# MKE18F16 register map
Vendor: Freescale Semiconductor, Inc.; Series: Kinetis_E; File version: 1.6
CPU: CM4 r0p1, little endian, no MPU, FPU, VTOR, 4 interrupt priority bits
Registers are 32-bit, read-write, reset 0x0 unless marked. A register's access mark holds for its fields unless they carry their own. Offsets are from the block's base; [hi:lo] are bit positions; {n}, {i} and the like mark numbered series; 'fields as' and 'values as' point back to an identical list.

## PCC
Base 0x40065000
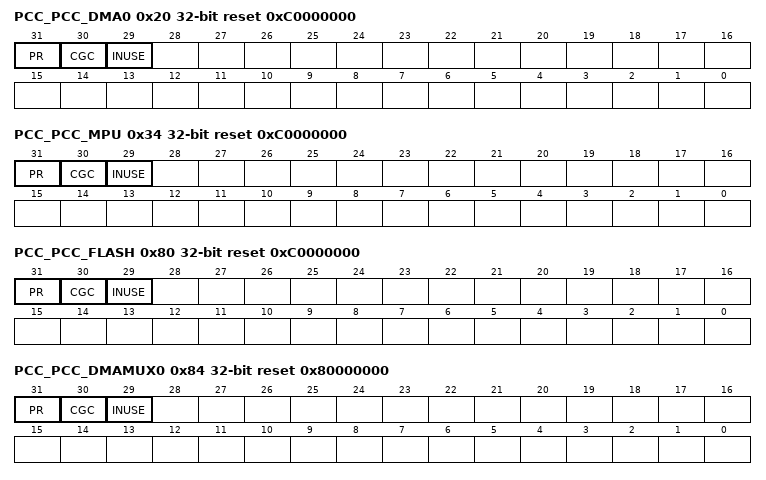
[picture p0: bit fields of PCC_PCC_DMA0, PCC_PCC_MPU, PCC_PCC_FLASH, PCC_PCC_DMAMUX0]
0x20 PCC_PCC_DMA0 reset 0xC0000000 — PCC Register
  [31] PR ro — Enable
    0=Peripheral is not present; 1=Peripheral is present
  [30] CGC — Clock Control
    0=Clock disabled; 1=Clock enabled
  [29] INUSE ro — Clock Gate Control
    0=Peripheral is not being used; 1=Peripheral is being used. Software cannot modify the existing clocking configuration.
0x34 PCC_PCC_MPU reset 0xC0000000 — PCC Register
  fields as PCC_PCC_DMA0
0x80 PCC_PCC_FLASH reset 0xC0000000 — PCC Register
  fields as PCC_PCC_DMA0
0x84 PCC_PCC_DMAMUX0 reset 0x80000000 — PCC Register
  fields as PCC_PCC_DMA0
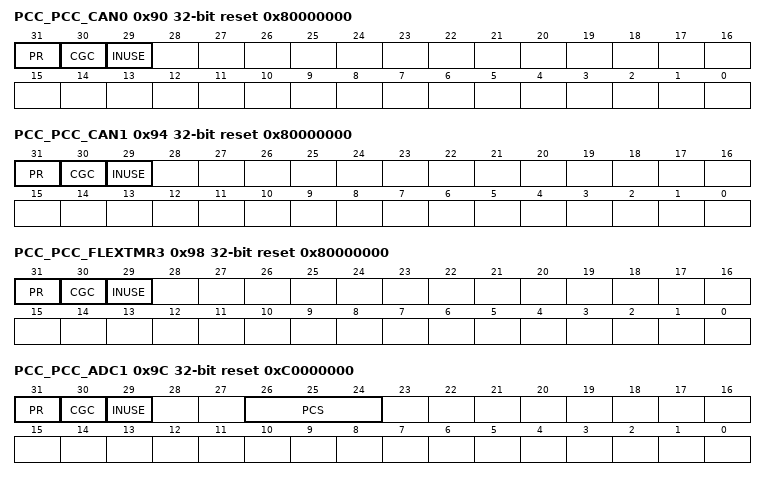
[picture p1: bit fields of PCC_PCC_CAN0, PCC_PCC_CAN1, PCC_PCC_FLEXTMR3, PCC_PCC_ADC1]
0x90 PCC_PCC_CAN0 reset 0x80000000 — PCC Register
  fields as PCC_PCC_DMA0
0x94 PCC_PCC_CAN1 reset 0x80000000 — PCC Register
  fields as PCC_PCC_DMA0
0x98 PCC_PCC_FLEXTMR3 reset 0x80000000 — PCC Register
  fields as PCC_PCC_DMA0
0x9C PCC_PCC_ADC1 reset 0xC0000000 — PCC Register
  [31] PR ro — Enable
    0=Peripheral is not present; 1=Peripheral is present
  [30] CGC — Clock Control
    0=Clock disabled; 1=Clock enabled
  [29] INUSE ro — Clock Gate Control
    values as PCC_PCC_DMA0.INUSE
  [26:24] PCS — Peripheral Clock Source Select
    0=Clock is off (or test clock is enabled); 1=OSCCLK - System Oscillator Bus Clock(scg_sosc_slow_clk); 2=SCGIRCLK - Slow IRC Clock(scg_sirc_slow_clk), (maximum is 8MHz); 3=SCGFIRCLK - Fast IRC Clock(scg_firc_slow_clk), (maximum is 48MHz); 6=SCGPCLK System PLL clock(scg_spll_slow_clk)
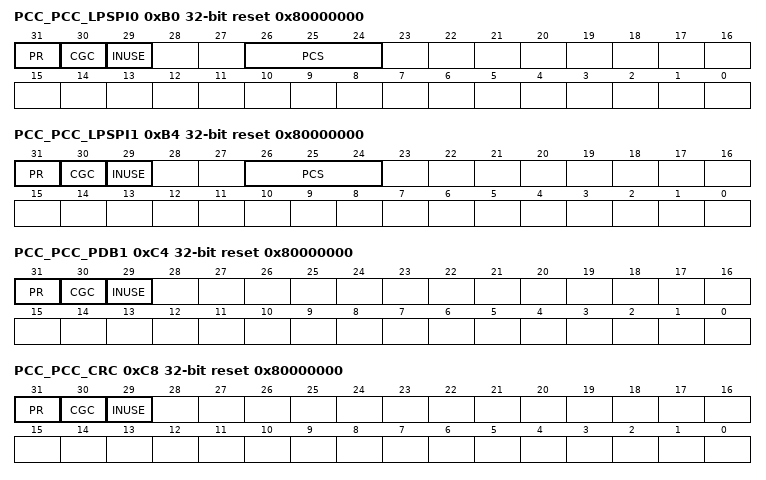
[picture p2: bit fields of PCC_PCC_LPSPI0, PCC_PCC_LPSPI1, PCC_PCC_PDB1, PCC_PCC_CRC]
0xB0 PCC_PCC_LPSPI0 reset 0x80000000 — PCC Register
  fields as PCC_PCC_ADC1
0xB4 PCC_PCC_LPSPI1 reset 0x80000000 — PCC Register
  fields as PCC_PCC_ADC1
0xC4 PCC_PCC_PDB1 reset 0x80000000 — PCC Register
  fields as PCC_PCC_DMA0
0xC8 PCC_PCC_CRC reset 0x80000000 — PCC Register
  fields as PCC_PCC_DMA0
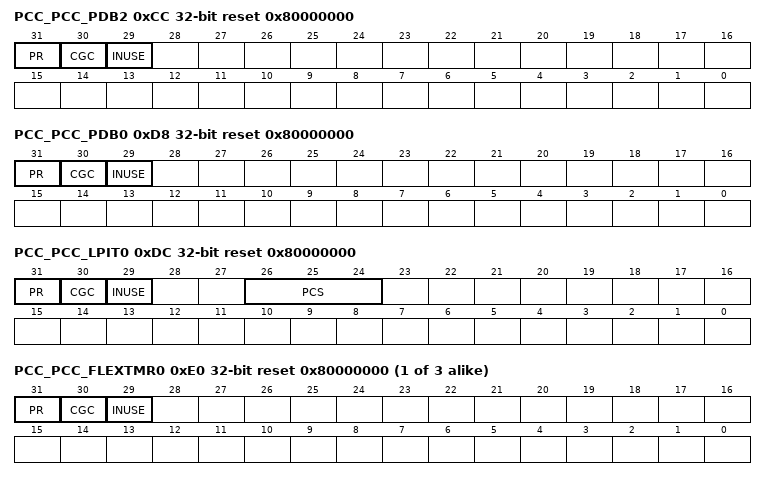
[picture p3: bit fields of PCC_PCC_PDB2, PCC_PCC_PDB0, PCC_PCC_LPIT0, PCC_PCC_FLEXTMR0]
0xCC PCC_PCC_PDB2 reset 0x80000000 — PCC Register
  fields as PCC_PCC_DMA0
0xD8 PCC_PCC_PDB0 reset 0x80000000 — PCC Register
  fields as PCC_PCC_DMA0
0xDC PCC_PCC_LPIT0 reset 0x80000000 — PCC Register
  fields as PCC_PCC_ADC1
{0xE0+4i} PCC_PCC_FLEXTMR{i} reset 0x80000000 (i=0..2) — PCC Register
  fields as PCC_PCC_DMA0
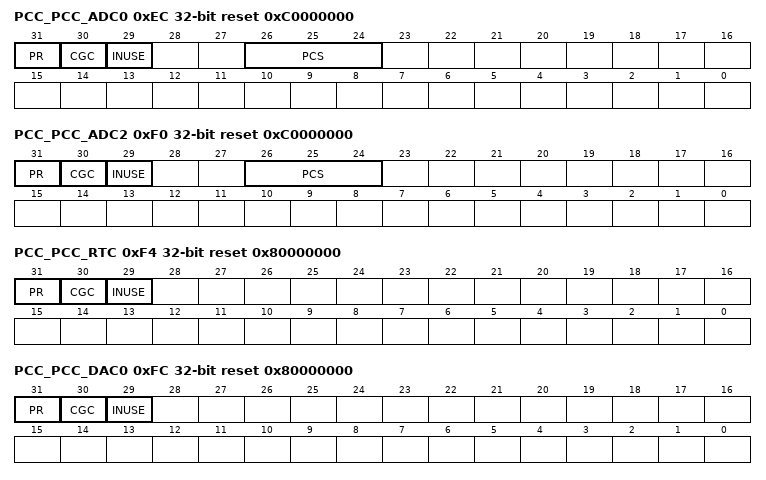
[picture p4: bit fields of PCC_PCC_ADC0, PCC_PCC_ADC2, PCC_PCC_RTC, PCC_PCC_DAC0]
0xEC PCC_PCC_ADC0 reset 0xC0000000 — PCC Register
  fields as PCC_PCC_ADC1
0xF0 PCC_PCC_ADC2 reset 0xC0000000 — PCC Register
  fields as PCC_PCC_ADC1
0xF4 PCC_PCC_RTC reset 0x80000000 — PCC Register
  fields as PCC_PCC_DMA0
0xFC PCC_PCC_DAC0 reset 0x80000000 — PCC Register
  fields as PCC_PCC_DMA0
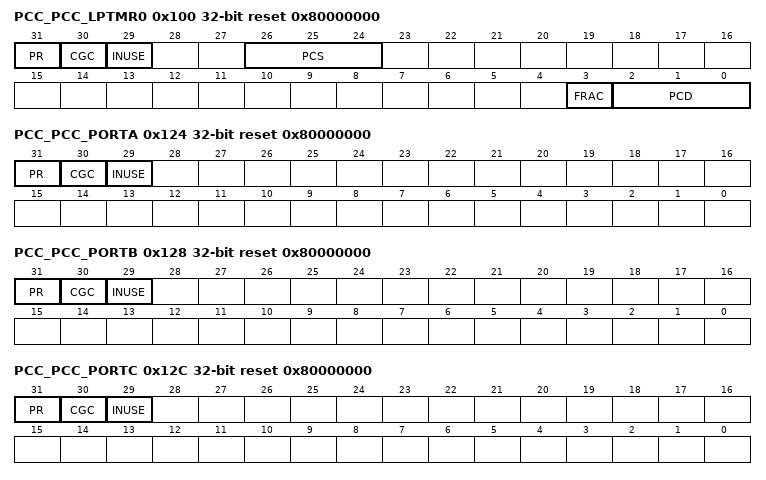
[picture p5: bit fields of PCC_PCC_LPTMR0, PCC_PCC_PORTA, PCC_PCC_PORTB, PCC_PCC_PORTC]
0x100 PCC_PCC_LPTMR0 reset 0x80000000 — PCC Register
  [31] PR ro — Enable
    0=Peripheral is not present; 1=Peripheral is present
  [30] CGC — Clock Control
    0=Clock disabled; 1=Clock enabled
  [29] INUSE ro — Clock Gate Control
    values as PCC_PCC_DMA0.INUSE
  [26:24] PCS — Peripheral Clock Source Select
    values as PCC_PCC_ADC1.PCS
  [3] FRAC — Peripheral Clock Divider Fraction
    0=Fractional value is 0; 1=Fractional value is 1
  [2:0] PCD — Peripheral Clock Divider Select
    0=Divide by 1 (pass-through, no clock divide); {v}=Divide by {v+1} (v=1..7)
0x124 PCC_PCC_PORTA reset 0x80000000 — PCC Register
  fields as PCC_PCC_DMA0
0x128 PCC_PCC_PORTB reset 0x80000000 — PCC Register
  fields as PCC_PCC_DMA0
0x12C PCC_PCC_PORTC reset 0x80000000 — PCC Register
  fields as PCC_PCC_DMA0
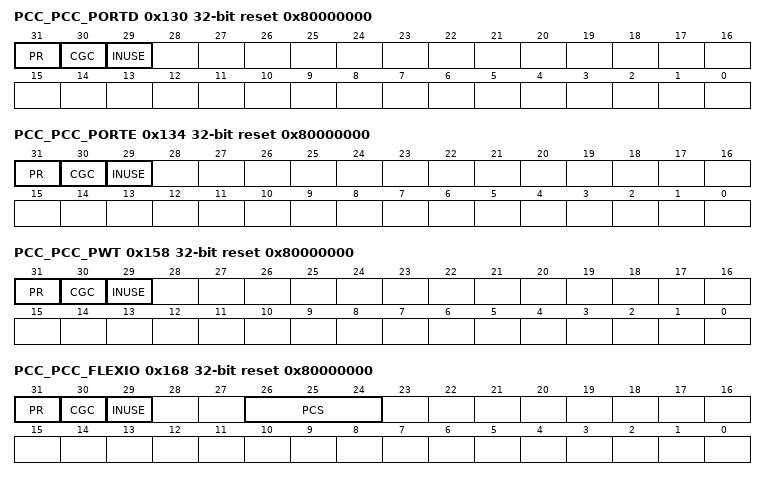
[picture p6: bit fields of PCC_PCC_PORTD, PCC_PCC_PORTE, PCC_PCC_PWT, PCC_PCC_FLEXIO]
0x130 PCC_PCC_PORTD reset 0x80000000 — PCC Register
  fields as PCC_PCC_DMA0
0x134 PCC_PCC_PORTE reset 0x80000000 — PCC Register
  fields as PCC_PCC_DMA0
0x158 PCC_PCC_PWT reset 0x80000000 — PCC Register
  fields as PCC_PCC_DMA0
0x168 PCC_PCC_FLEXIO reset 0x80000000 — PCC Register
  fields as PCC_PCC_ADC1
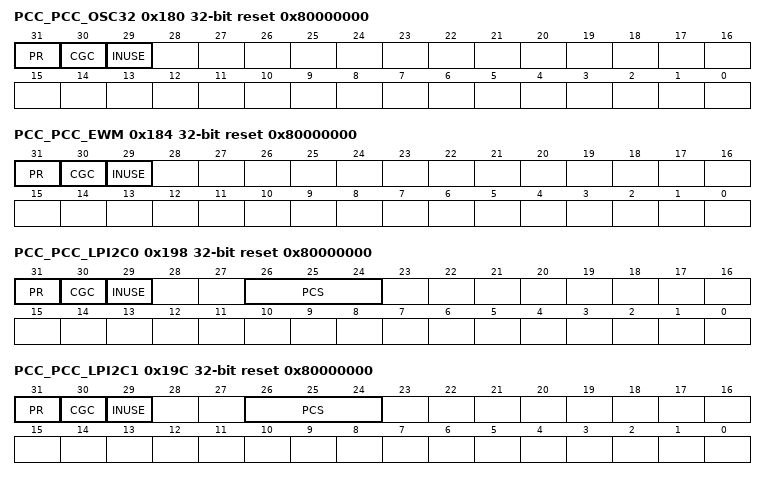
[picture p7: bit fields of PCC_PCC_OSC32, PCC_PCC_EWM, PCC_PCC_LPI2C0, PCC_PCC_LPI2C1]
0x180 PCC_PCC_OSC32 reset 0x80000000 — PCC Register
  fields as PCC_PCC_DMA0
0x184 PCC_PCC_EWM reset 0x80000000 — PCC Register
  fields as PCC_PCC_DMA0
0x198 PCC_PCC_LPI2C0 reset 0x80000000 — PCC Register
  fields as PCC_PCC_ADC1
0x19C PCC_PCC_LPI2C1 reset 0x80000000 — PCC Register
  fields as PCC_PCC_ADC1
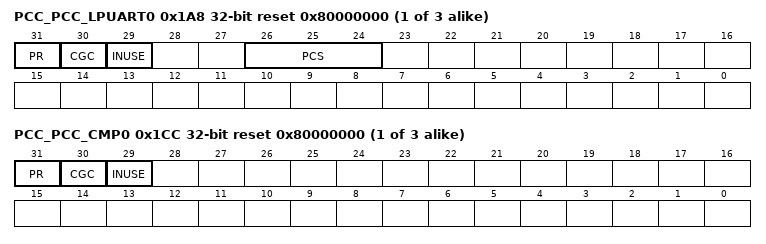
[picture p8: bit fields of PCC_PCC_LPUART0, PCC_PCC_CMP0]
{0x1A8+4i} PCC_PCC_LPUART{i} reset 0x80000000 (i=0..2) — PCC Register
  fields as PCC_PCC_ADC1
{0x1CC+4i} PCC_PCC_CMP{i} reset 0x80000000 (i=0..2) — PCC Register
  fields as PCC_PCC_DMA0
